# RE01_256KB register map
Vendor: Renesas Electronics Corporation; Series: RE01; File version: 1.00.01
CPU: CM0PLUS r0p1, little endian, MPU, no FPU, VTOR, 2 interrupt priority bits, 32 interrupts
Registers are 8-bit, read-write, reset 0x0 unless marked. A register's access mark holds for its fields unless they carry their own. Offsets are from the block's base; [hi:lo] are bit positions; {n}, {i} and the like mark numbered series; 'fields as' and 'values as' point back to an identical list.

## ELC — Event Link Controller
Base 0x40041000
0x00 ELCR — Event Link Control Registers
  [7] ELCON — All Event Link Enable
    0=Disable ELC function; 1=Enable ELC function
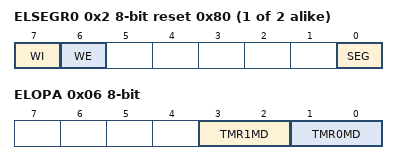
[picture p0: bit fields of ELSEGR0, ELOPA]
{0x2+2i} ELSEGR{i} (i=0..1) reset 0x80 — Event Link Software Event Generation Register {i}
  [7] WI wo — ELSEGRn Register Write Disable
    0=Enable writes to the ELSEGRn register; 1=Disable writes to the ELSEGRn register
  [6] WE — SEG Bit Write Enable
    0=Disable writes to the SEG bit; 1=Enable writes to the SEG bit
  [0] SEG wo — Software Event Generation
    0=Normal operation; 1=Software event is generated
0x06 ELOPA — Event Link Option Setting Register A
  [3:2] TMR1MD — TMR1 Operation Select Bit
    0=Disable event; 1=Start count; 2=Restart counter; 3=Event counter
  [1:0] TMR0MD — TMR0 Operation Select Bit
    values as TMR1MD
{0x10+4i} ELSR{i} (i=0..3) 16-bit — Event Link Setting Register {i}
  [7:0] ELS — Event Link Select
{0x10+4i} ELSR{i} (i=6..8) 16-bit — Event Link Setting Register {i}
  [7:0] ELS — Event Link Select
{0x10+4i} ELSR{i} (i=14..15) 16-bit — Event Link Setting Register {i}
  [7:0] ELS — Event Link Select
{0x10+4i} ELSR{i} (i=18..19) 16-bit — Event Link Setting Register {i}
  [7:0] ELS — Event Link Select

## POE — Port Output Enable Module for GPT
Base 0x40042000
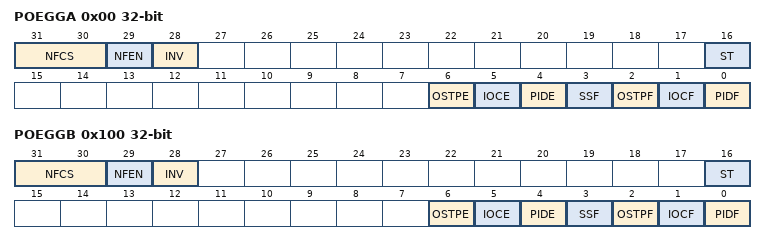
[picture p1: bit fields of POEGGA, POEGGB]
0x00 POEGGA 32-bit — POE Group A Setting Register
  [31:30] NFCS — Noise Filter Clock Select
    0=Sample GTETRGn pin input level three times every PCLKB; 1=Sample GTETRGn pin input level three times every PCLKB/8; 2=Sample GTETRGn pin input level three times every PCLKB/32; 3=Sample GTETRGn pin input level three times every PCLKB/128
  [29] NFEN — Noise Filter Enable
    0=Disable noise filtering; 1=Enable noise filtering
  [28] INV — GTETRGn Input Reverse
    0=Input GTETRGn as-is; 1=Input GTETRGn in reverse
  [16] ST ro — GTETRGn Input Status Flag
    0=GTETRGn input after filtering was 0; 1=GTETRGn input after filtering was 1
  [6] OSTPE — Oscillation Stop Detection Enable
    0=Disable output-disable requests from oscillation stop detection; 1=Enable output-disable requests from oscillation stop detection
  [5] IOCE — Enable for GPT Output-Disable Request
    0=Disable output-disable requests from GPT; 1=Enable output-disable requests from GPT
  [4] PIDE — Port Input Detection Enable
    0=Disable output-disable requests from the GTETRGn pins; 1=Enable output-disable requests from the GTETRGn pins
  [3] SSF — Software Stop Flag
    0=No output-disable request from software occurred; 1=Output-disable request from software occurred
  [2] OSTPF — Oscillation Stop Detection Flag
    0=No output-disable request from oscillation stop detection occurred; 1=Output-disable request from oscillation stop detection occurred
  [1] IOCF — Detection Flag for GPT Output-Disable Request
    0=No output-disable request from GPT occurred; 1=Output-disable request from GPT occurred
  [0] PIDF — Port Input Detection Flag
    0=No output-disable request from the GTETRGn pin occurred; 1=Output-disable request from the GTETRGn pin occurred
0x100 POEGGB 32-bit — POE Group B Setting Register
  fields as POEGGA

## WDT — Watchdog Timer
Base 0x40044200
0x00 WDTRR reset 0xFF — WDT Refresh Register
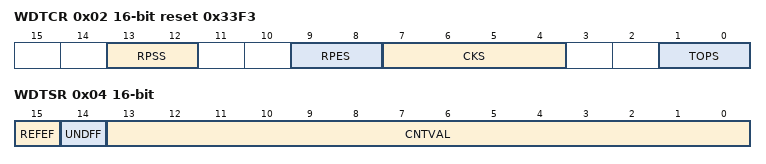
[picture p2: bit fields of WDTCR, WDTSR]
0x02 WDTCR 16-bit reset 0x33F3 — WDT Control Register
  [13:12] RPSS — Window Start Position Select
    0=25%; 1=50%; 2=75%; 3=100% (do not specify window start position)
  [9:8] RPES — Window End Position Select
    0=75%; 1=50%; 2=25%; 3=0% (do not specify window end position)
  [7:4] CKS — Clock Division Ratio Select
    1=WDTCLK/4; 4=WDTCLK/64; 15=WDTCLK/128; 6=WDTCLK/512; 7=WDTCLK/2048; 8=WDTCLK/8192; other=Others (Setting prohibited)
  [1:0] TOPS — Timeout Period Select
    0=1024 cycles (0x03FF); 1=4096 cycles (0x0FFF); 2=8192 cycles (0x1FFF); 3=16384 cycles (0x3FFF)
0x04 WDTSR 16-bit — WDT Status Register
  [15] REFEF — Refresh Error Flag
    0=No refresh error occurred; 1=Refresh error occurred
  [14] UNDFF — Underflow Flag
    0=No underflow occurred; 1=Underflow occurred
  [13:0] CNTVAL ro — Down-Counter Value
0x06 WDTRCR reset 0x80 — WDT Reset Control Register
  [7] RSTIRQS — Reset Interrupt Request Select
    0=Enable non-maskable interrupt request or interrupt request output; 1=Enable reset output
0x08 WDTCSTPR reset 0x80 — WDT Count Stop Control Register
  [7] SLCSTP
    0=Disable count stop; 1=Stop count on transition to Sleep mode
